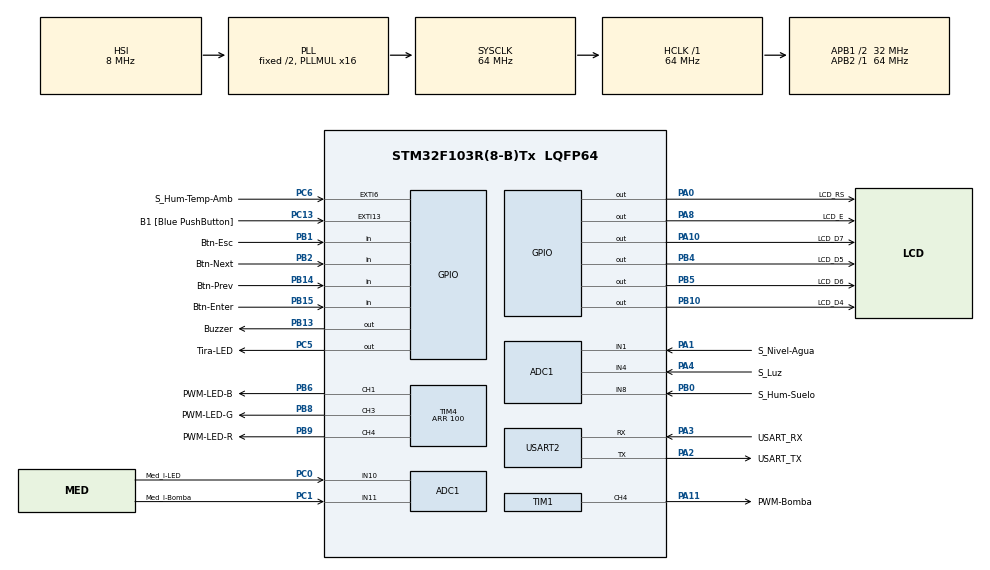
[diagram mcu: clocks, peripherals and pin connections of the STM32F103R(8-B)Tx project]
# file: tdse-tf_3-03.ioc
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ADC1.Channel-3\#ChannelRegularConversion=ADC_CHANNEL_1
ADC1.NbrOfConversionFlag=1
ADC1.Rank-3\#ChannelRegularConversion=1
ADC1.SamplingTime-3\#ChannelRegularConversion=ADC_SAMPLETIME_239CYCLES_5
ADC1.master=1
Mcu.Family=STM32F1
Mcu.Name=STM32F103R(8-B)Tx
Mcu.Package=LQFP64
NVIC.ADC1_2_IRQn=true\:2\:0\:true\:false\:true\:true\:true\:true
NVIC.EXTI9_5_IRQn=true\:0\:0\:false\:false\:true\:true\:true\:true
NVIC.PriorityGroup=NVIC_PRIORITYGROUP_4
PA0-WKUP.GPIO_Label=LCD_RS
PA0-WKUP.Signal=GPIO_Output
PA1.GPIO_Label=S_Nivel-Agua
PA1.Signal=ADCx_IN1
PA10.GPIO_Label=LCD_D7
PA10.Signal=GPIO_Output
PA11.GPIO_Label=PWM-Bomba
PA11.Signal=S_TIM1_CH4
PA13.GPIO_Label=TMS
PA13.Mode=Serial_Wire
PA13.Signal=SYS_JTMS-SWDIO
PA14.GPIO_Label=TCK
PA14.Mode=Serial_Wire
PA14.Signal=SYS_JTCK-SWCLK
PA2.GPIO_Label=USART_TX
PA2.GPIO_Mode=GPIO_MODE_AF_PP
PA2.GPIO_PuPd=GPIO_NOPULL
PA2.GPIO_Speed=GPIO_SPEED_FREQ_LOW
PA2.Mode=Asynchronous
PA2.Signal=USART2_TX
PA3.GPIO_Label=USART_RX
PA3.GPIO_Mode=GPIO_MODE_AF_PP
PA3.GPIO_PuPd=GPIO_NOPULL
PA3.GPIO_Speed=GPIO_SPEED_FREQ_LOW
PA3.Mode=Asynchronous
PA3.Signal=USART2_RX
PA4.GPIO_Label=S_Luz
PA4.Signal=ADCx_IN4
PA8.GPIO_Label=LCD_E
PA8.Signal=GPIO_Output
PB0.GPIO_Label=S_Hum-Suelo
PB0.Signal=ADCx_IN8
PB1.GPIO_Label=Btn-Esc
PB1.GPIO_PuPd=GPIO_PULLUP
PB1.Signal=GPIO_Input
PB10.GPIO_Label=LCD_D4
PB10.GPIO_PuPd=GPIO_NOPULL
PB10.Signal=GPIO_Output
PB13.GPIO_Label=Buzzer
PB13.Signal=GPIO_Output
PB14.GPIO_Label=Btn-Prev
PB14.GPIO_PuPd=GPIO_PULLUP
PB14.Signal=GPIO_Input
PB15.GPIO_Label=Btn-Enter
PB15.GPIO_PuPd=GPIO_PULLUP
PB15.Signal=GPIO_Input
PB2.GPIO_Label=Btn-Next
PB2.GPIO_PuPd=GPIO_PULLUP
PB2.Signal=GPIO_Input
PB3.GPIO_Label=SWO
PB3.Signal=SYS_JTDO-TRACESWO
PB4.GPIO_Label=LCD_D5
PB4.GPIO_PuPd=GPIO_NOPULL
PB4.Signal=GPIO_Output
PB5.GPIO_Label=LCD_D6
PB5.Signal=GPIO_Output
PB6.GPIO_Label=PWM-LED-B
PB6.Signal=S_TIM4_CH1
PB8.GPIO_Label=PWM-LED-G
PB8.Signal=S_TIM4_CH3
PB9.GPIO_Label=PWM-LED-R
PB9.Signal=S_TIM4_CH4
PC0.GPIO_Label=Med_I-LED
PC0.Signal=ADCx_IN10
PC1.GPIO_Label=Med_I-Bomba
PC1.Signal=ADCx_IN11
PC13-TAMPER-RTC.GPIO_Label=B1 [Blue PushButton]
PC13-TAMPER-RTC.GPIO_PuPd=GPIO_NOPULL
PC13-TAMPER-RTC.Signal=GPXTI13
PC14-OSC32_IN.Mode=LSE-External-Oscillator
PC14-OSC32_IN.Signal=RCC_OSC32_IN
PC15-OSC32_OUT.Mode=LSE-External-Oscillator
PC15-OSC32_OUT.Signal=RCC_OSC32_OUT
PC5.GPIO_Label=Tira-LED
PC5.GPIO_PuPd=GPIO_PULLDOWN
PC5.Signal=GPIO_Output
PC6.GPIO_Label=S_Hum-Temp-Amb
PC6.Signal=GPXTI6
PD0-OSC_IN.Mode=HSE-External-Clock-Source
PD0-OSC_IN.Signal=RCC_OSC_IN
PD1-OSC_OUT.Mode=HSE-External-Clock-Source
PD1-OSC_OUT.Signal=RCC_OSC_OUT
ProjectManager.HeapSize=0x200
ProjectManager.StackSize=0x400
ProjectManager.TargetToolchain=STM32CubeIDE
RCC.ADCPresc=RCC_ADCPCLK2_DIV6
RCC.AHBFreq_Value=64000000
RCC.APB1CLKDivider=RCC_HCLK_DIV2
RCC.APB1Freq_Value=32000000
RCC.APB1TimFreq_Value=64000000
RCC.APB2Freq_Value=64000000
RCC.APB2TimFreq_Value=64000000
RCC.HCLKFreq_Value=64000000
RCC.PLLMUL=RCC_PLL_MUL16
RCC.RTCClockSelection=RCC_RTCCLKSOURCE_LSE
RCC.SYSCLKFreq_VALUE=64000000
RCC.SYSCLKSource=RCC_SYSCLKSOURCE_PLLCLK
RCC.USBFreq_Value=64000000
SH.ADCx_IN1.0=ADC1_IN1,IN1
SH.ADCx_IN10.0=ADC1_IN10,IN10
SH.ADCx_IN11.0=ADC1_IN11,IN11
SH.ADCx_IN4.0=ADC1_IN4,IN4
SH.ADCx_IN8.0=ADC1_IN8,IN8
SH.S_TIM1_CH4.0=TIM1_CH4,PWM Generation4 CH4
SH.S_TIM4_CH1.0=TIM4_CH1,PWM Generation1 CH1
SH.S_TIM4_CH3.0=TIM4_CH3,PWM Generation3 CH3
SH.S_TIM4_CH4.0=TIM4_CH4,PWM Generation4 CH4
TIM1.Channel-PWM\ Generation4\ CH4=TIM_CHANNEL_4
TIM2.Prescaler=63
TIM4.Channel-PWM\ Generation1\ CH1=TIM_CHANNEL_1
TIM4.Channel-PWM\ Generation3\ CH3=TIM_CHANNEL_3
TIM4.Channel-PWM\ Generation4\ CH4=TIM_CHANNEL_4
TIM4.Period=100
USART2.VirtualMode=VM_ASYNC
VP_TIM2_VS_ClockSourceINT.Mode=Internal
board=NUCLEO-F103RB

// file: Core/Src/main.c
/* USER CODE BEGIN Header */
/**
  ******************************************************************************
  * @file           : main.c
  * @brief          : Main program body
  ******************************************************************************
  * @attention
  *
  * Copyright (c) 2025 STMicroelectronics.
  * All rights reserved.
  *
  * This software is licensed under terms that can be found in the LICENSE file
  * in the root directory of this software component.
  * If no LICENSE file comes with this software, it is provided AS-IS.
  *
  ******************************************************************************
  */
/* USER CODE END Header */
#include "main.h"

/* USER CODE BEGIN Includes */

/* Application includes. */
#include "logger.h"
#include "app.h"
#include "task_dht22.h"
/* USER CODE END Includes */

ADC_HandleTypeDef hadc1;

TIM_HandleTypeDef htim1;
TIM_HandleTypeDef htim2;
TIM_HandleTypeDef htim4;

UART_HandleTypeDef huart2;

void SystemClock_Config(void);
static void MX_GPIO_Init(void);
static void MX_USART2_UART_Init(void);
static void MX_ADC1_Init(void);
static void MX_TIM2_Init(void);
static void MX_TIM1_Init(void);
static void MX_TIM4_Init(void);

/* USER CODE BEGIN 0 */
#if (1 == LOGGER_CONFIG_USE_SEMIHOSTING)

extern void initialise_monitor_handles(void);

#endif

/* USER CODE END 0 */

int main(void)
{

  /* USER CODE BEGIN 1 */
  #if (1 == LOGGER_CONFIG_USE_SEMIHOSTING)

	initialise_monitor_handles();

  #endif

  /* USER CODE END 1 */

  /* MCU Configuration--------------------------------------------------------*/

  /* Reset of all peripherals, Initializes the Flash interface and the Systick. */
  HAL_Init();

  /* Configure the system clock */
  SystemClock_Config();

  /* Initialize all configured peripherals */
  MX_GPIO_Init();
  MX_USART2_UART_Init();
  MX_ADC1_Init();
  MX_TIM2_Init();
  MX_TIM1_Init();
  MX_TIM4_Init();
  /* USER CODE BEGIN 2 */

  HAL_TIM_Base_Start(&htim2);

  /* Application Init */
  app_init();

  /* USER CODE END 2 */

  /* Infinite loop */
  while (1)
  {

    /* USER CODE BEGIN 3 */

    /* Application Update */
    app_update();
  }
  /* USER CODE END 3 */
}

void SystemClock_Config(void)
{
  RCC_OscInitTypeDef RCC_OscInitStruct = {0};
  RCC_ClkInitTypeDef RCC_ClkInitStruct = {0};
  RCC_PeriphCLKInitTypeDef PeriphClkInit = {0};

  /** Initializes the RCC Oscillators according to the specified parameters
  * in the RCC_OscInitTypeDef structure.
  */
  RCC_OscInitStruct.OscillatorType = RCC_OSCILLATORTYPE_HSI;
  RCC_OscInitStruct.HSIState = RCC_HSI_ON;
  RCC_OscInitStruct.HSICalibrationValue = RCC_HSICALIBRATION_DEFAULT;
  RCC_OscInitStruct.PLL.PLLState = RCC_PLL_ON;
  RCC_OscInitStruct.PLL.PLLSource = RCC_PLLSOURCE_HSI_DIV2;
  RCC_OscInitStruct.PLL.PLLMUL = RCC_PLL_MUL16;
  if (HAL_RCC_OscConfig(&RCC_OscInitStruct) != HAL_OK)
  {
    Error_Handler();
  }

  /** Initializes the CPU, AHB and APB buses clocks
  */
  RCC_ClkInitStruct.ClockType = RCC_CLOCKTYPE_HCLK|RCC_CLOCKTYPE_SYSCLK
                              |RCC_CLOCKTYPE_PCLK1|RCC_CLOCKTYPE_PCLK2;
  RCC_ClkInitStruct.SYSCLKSource = RCC_SYSCLKSOURCE_PLLCLK;
  RCC_ClkInitStruct.AHBCLKDivider = RCC_SYSCLK_DIV1;
  RCC_ClkInitStruct.APB1CLKDivider = RCC_HCLK_DIV2;
  RCC_ClkInitStruct.APB2CLKDivider = RCC_HCLK_DIV1;

  if (HAL_RCC_ClockConfig(&RCC_ClkInitStruct, FLASH_LATENCY_2) != HAL_OK)
  {
    Error_Handler();
  }
  PeriphClkInit.PeriphClockSelection = RCC_PERIPHCLK_ADC;
  PeriphClkInit.AdcClockSelection = RCC_ADCPCLK2_DIV6;
  if (HAL_RCCEx_PeriphCLKConfig(&PeriphClkInit) != HAL_OK)
  {
    Error_Handler();
  }
}

static void MX_ADC1_Init(void)
{

  ADC_ChannelConfTypeDef sConfig = {0};

  /** Common config
  */
  hadc1.Instance = ADC1;
  hadc1.Init.ScanConvMode = ADC_SCAN_DISABLE;
  hadc1.Init.ContinuousConvMode = DISABLE;
  hadc1.Init.DiscontinuousConvMode = DISABLE;
  hadc1.Init.ExternalTrigConv = ADC_SOFTWARE_START;
  hadc1.Init.DataAlign = ADC_DATAALIGN_RIGHT;
  hadc1.Init.NbrOfConversion = 1;
  if (HAL_ADC_Init(&hadc1) != HAL_OK)
  {
    Error_Handler();
  }

  /** Configure Regular Channel
  */
  sConfig.Channel = ADC_CHANNEL_1;
  sConfig.Rank = ADC_REGULAR_RANK_1;
  sConfig.SamplingTime = ADC_SAMPLETIME_239CYCLES_5;
  if (HAL_ADC_ConfigChannel(&hadc1, &sConfig) != HAL_OK)
  {
    Error_Handler();
  }

}

static void MX_TIM1_Init(void)
{

  TIM_MasterConfigTypeDef sMasterConfig = {0};
  TIM_OC_InitTypeDef sConfigOC = {0};
  TIM_BreakDeadTimeConfigTypeDef sBreakDeadTimeConfig = {0};

  htim1.Instance = TIM1;
  htim1.Init.Prescaler = 19;
  htim1.Init.CounterMode = TIM_COUNTERMODE_UP;
  htim1.Init.Period = 3199;
  htim1.Init.ClockDivision = TIM_CLOCKDIVISION_DIV1;
  htim1.Init.RepetitionCounter = 0;
  htim1.Init.AutoReloadPreload = TIM_AUTORELOAD_PRELOAD_DISABLE;
  if (HAL_TIM_PWM_Init(&htim1) != HAL_OK)
  {
    Error_Handler();
  }
  sMasterConfig.MasterOutputTrigger = TIM_TRGO_RESET;
  sMasterConfig.MasterSlaveMode = TIM_MASTERSLAVEMODE_DISABLE;
  if (HAL_TIMEx_MasterConfigSynchronization(&htim1, &sMasterConfig) != HAL_OK)
  {
    Error_Handler();
  }
  sConfigOC.OCMode = TIM_OCMODE_PWM1;
  sConfigOC.Pulse = 0;
  sConfigOC.OCPolarity = TIM_OCPOLARITY_HIGH;
  sConfigOC.OCFastMode = TIM_OCFAST_DISABLE;
  sConfigOC.OCIdleState = TIM_OCIDLESTATE_RESET;
  sConfigOC.OCNIdleState = TIM_OCNIDLESTATE_RESET;
  if (HAL_TIM_PWM_ConfigChannel(&htim1, &sConfigOC, TIM_CHANNEL_4) != HAL_OK)
  {
    Error_Handler();
  }
  sBreakDeadTimeConfig.OffStateRunMode = TIM_OSSR_DISABLE;
  sBreakDeadTimeConfig.OffStateIDLEMode = TIM_OSSI_DISABLE;
  sBreakDeadTimeConfig.LockLevel = TIM_LOCKLEVEL_OFF;
  sBreakDeadTimeConfig.DeadTime = 0;
  sBreakDeadTimeConfig.BreakState = TIM_BREAK_DISABLE;
  sBreakDeadTimeConfig.BreakPolarity = TIM_BREAKPOLARITY_HIGH;
  sBreakDeadTimeConfig.AutomaticOutput = TIM_AUTOMATICOUTPUT_DISABLE;
  if (HAL_TIMEx_ConfigBreakDeadTime(&htim1, &sBreakDeadTimeConfig) != HAL_OK)
  {
    Error_Handler();
  }
  HAL_TIM_MspPostInit(&htim1);

}

static void MX_TIM2_Init(void)
{

  TIM_ClockConfigTypeDef sClockSourceConfig = {0};
  TIM_MasterConfigTypeDef sMasterConfig = {0};

  htim2.Instance = TIM2;
  htim2.Init.Prescaler = 63;
  htim2.Init.CounterMode = TIM_COUNTERMODE_UP;
  htim2.Init.Period = 65535;
  htim2.Init.ClockDivision = TIM_CLOCKDIVISION_DIV1;
  htim2.Init.AutoReloadPreload = TIM_AUTORELOAD_PRELOAD_DISABLE;
  if (HAL_TIM_Base_Init(&htim2) != HAL_OK)
  {
    Error_Handler();
  }
  sClockSourceConfig.ClockSource = TIM_CLOCKSOURCE_INTERNAL;
  if (HAL_TIM_ConfigClockSource(&htim2, &sClockSourceConfig) != HAL_OK)
  {
    Error_Handler();
  }
  sMasterConfig.MasterOutputTrigger = TIM_TRGO_RESET;
  sMasterConfig.MasterSlaveMode = TIM_MASTERSLAVEMODE_DISABLE;
  if (HAL_TIMEx_MasterConfigSynchronization(&htim2, &sMasterConfig) != HAL_OK)
  {
    Error_Handler();
  }

}

static void MX_TIM4_Init(void)
{

  TIM_MasterConfigTypeDef sMasterConfig = {0};
  TIM_OC_InitTypeDef sConfigOC = {0};

  htim4.Instance = TIM4;
  htim4.Init.Prescaler = 0;
  htim4.Init.CounterMode = TIM_COUNTERMODE_UP;
  htim4.Init.Period = 100;
  htim4.Init.ClockDivision = TIM_CLOCKDIVISION_DIV1;
  htim4.Init.AutoReloadPreload = TIM_AUTORELOAD_PRELOAD_DISABLE;
  if (HAL_TIM_PWM_Init(&htim4) != HAL_OK)
  {
    Error_Handler();
  }
  sMasterConfig.MasterOutputTrigger = TIM_TRGO_RESET;
  sMasterConfig.MasterSlaveMode = TIM_MASTERSLAVEMODE_DISABLE;
  if (HAL_TIMEx_MasterConfigSynchronization(&htim4, &sMasterConfig) != HAL_OK)
  {
    Error_Handler();
  }
  sConfigOC.OCMode = TIM_OCMODE_PWM1;
  sConfigOC.Pulse = 0;
  sConfigOC.OCPolarity = TIM_OCPOLARITY_HIGH;
  sConfigOC.OCFastMode = TIM_OCFAST_DISABLE;
  if (HAL_TIM_PWM_ConfigChannel(&htim4, &sConfigOC, TIM_CHANNEL_1) != HAL_OK)
  {
    Error_Handler();
  }
  if (HAL_TIM_PWM_ConfigChannel(&htim4, &sConfigOC, TIM_CHANNEL_3) != HAL_OK)
  {
    Error_Handler();
  }
  if (HAL_TIM_PWM_ConfigChannel(&htim4, &sConfigOC, TIM_CHANNEL_4) != HAL_OK)
  {
    Error_Handler();
  }
  HAL_TIM_MspPostInit(&htim4);

}

static void MX_USART2_UART_Init(void)
{

  huart2.Instance = USART2;
  huart2.Init.BaudRate = 115200;
  huart2.Init.WordLength = UART_WORDLENGTH_8B;
  huart2.Init.StopBits = UART_STOPBITS_1;
  huart2.Init.Parity = UART_PARITY_NONE;
  huart2.Init.Mode = UART_MODE_TX_RX;
  huart2.Init.HwFlowCtl = UART_HWCONTROL_NONE;
  huart2.Init.OverSampling = UART_OVERSAMPLING_16;
  if (HAL_UART_Init(&huart2) != HAL_OK)
  {
    Error_Handler();
  }

}

static void MX_GPIO_Init(void)
{
  GPIO_InitTypeDef GPIO_InitStruct = {0};

  /* GPIO Ports Clock Enable */
  __HAL_RCC_GPIOC_CLK_ENABLE();
  __HAL_RCC_GPIOD_CLK_ENABLE();
  __HAL_RCC_GPIOA_CLK_ENABLE();
  __HAL_RCC_GPIOB_CLK_ENABLE();

  /*Configure GPIO pin Output Level */
  HAL_GPIO_WritePin(GPIOA, LCD_RS_Pin|LCD_E_Pin|LCD_D7_Pin, GPIO_PIN_RESET);

  /*Configure GPIO pin Output Level */
  HAL_GPIO_WritePin(Tira_LED_GPIO_Port, Tira_LED_Pin, GPIO_PIN_RESET);

  /*Configure GPIO pin Output Level */
  HAL_GPIO_WritePin(GPIOB, LCD_D4_Pin|Buzzer_Pin|LCD_D5_Pin|LCD_D6_Pin, GPIO_PIN_RESET);

  /*Configure GPIO pins : B1_Pin S_Hum_Temp_Amb_Pin */
  GPIO_InitStruct.Pin = B1_Pin|S_Hum_Temp_Amb_Pin;
  GPIO_InitStruct.Mode = GPIO_MODE_IT_RISING;
  GPIO_InitStruct.Pull = GPIO_NOPULL;
  HAL_GPIO_Init(GPIOC, &GPIO_InitStruct);

  /*Configure GPIO pins : LCD_RS_Pin LCD_E_Pin LCD_D7_Pin */
  GPIO_InitStruct.Pin = LCD_RS_Pin|LCD_E_Pin|LCD_D7_Pin;
  GPIO_InitStruct.Mode = GPIO_MODE_OUTPUT_PP;
  GPIO_InitStruct.Pull = GPIO_NOPULL;
  GPIO_InitStruct.Speed = GPIO_SPEED_FREQ_LOW;
  HAL_GPIO_Init(GPIOA, &GPIO_InitStruct);

  /*Configure GPIO pin : Tira_LED_Pin */
  GPIO_InitStruct.Pin = Tira_LED_Pin;
  GPIO_InitStruct.Mode = GPIO_MODE_OUTPUT_PP;
  GPIO_InitStruct.Pull = GPIO_PULLDOWN;
  GPIO_InitStruct.Speed = GPIO_SPEED_FREQ_LOW;
  HAL_GPIO_Init(Tira_LED_GPIO_Port, &GPIO_InitStruct);

  /*Configure GPIO pins : Btn_Esc_Pin Btn_Next_Pin Btn_Prev_Pin Btn_Enter_Pin */
  GPIO_InitStruct.Pin = Btn_Esc_Pin|Btn_Next_Pin|Btn_Prev_Pin|Btn_Enter_Pin;
  GPIO_InitStruct.Mode = GPIO_MODE_INPUT;
  GPIO_InitStruct.Pull = GPIO_PULLUP;
  HAL_GPIO_Init(GPIOB, &GPIO_InitStruct);

  /*Configure GPIO pins : LCD_D4_Pin Buzzer_Pin LCD_D5_Pin LCD_D6_Pin */
  GPIO_InitStruct.Pin = LCD_D4_Pin|Buzzer_Pin|LCD_D5_Pin|LCD_D6_Pin;
  GPIO_InitStruct.Mode = GPIO_MODE_OUTPUT_PP;
  GPIO_InitStruct.Pull = GPIO_NOPULL;
  GPIO_InitStruct.Speed = GPIO_SPEED_FREQ_LOW;
  HAL_GPIO_Init(GPIOB, &GPIO_InitStruct);

  /* EXTI interrupt init*/
  HAL_NVIC_SetPriority(EXTI9_5_IRQn, 0, 0);
  HAL_NVIC_EnableIRQ(EXTI9_5_IRQn);

}

/* USER CODE BEGIN 4 */
void HAL_GPIO_EXTI_Callback(uint16_t GPIO_Pin)
{
    task_dht22_exti_callback(GPIO_Pin);
}
/* USER CODE END 4 */

void Error_Handler(void)
{
  __disable_irq();
  while (1)
  {
  }
}
